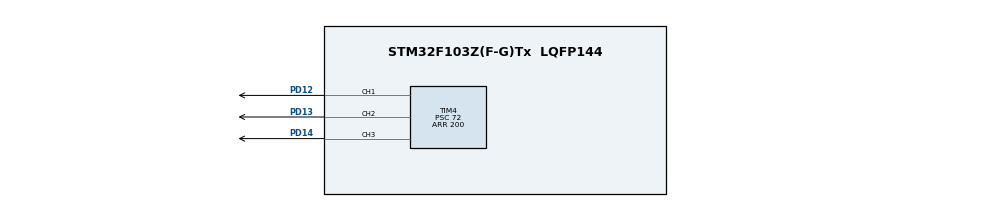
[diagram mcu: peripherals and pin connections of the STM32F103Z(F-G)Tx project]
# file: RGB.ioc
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Mcu.Family=STM32F1
Mcu.Name=STM32F103Z(F-G)Tx
Mcu.Package=LQFP144
NVIC.PriorityGroup=NVIC_PRIORITYGROUP_4
PA13.Mode=Serial_Wire
PA13.Signal=SYS_JTMS-SWDIO
PA14.Mode=Serial_Wire
PA14.Signal=SYS_JTCK-SWCLK
PD12.Signal=S_TIM4_CH1
PD13.Signal=S_TIM4_CH2
PD14.Signal=S_TIM4_CH3
ProjectManager.HeapSize=0x200
ProjectManager.StackSize=0x400
ProjectManager.TargetToolchain=MDK-ARM V5.27
RCC.APB1Freq_Value=8000000
RCC.APB2Freq_Value=8000000
SH.S_TIM4_CH1.0=TIM4_CH1,PWM Generation1 CH1
SH.S_TIM4_CH2.0=TIM4_CH2,PWM Generation2 CH2
SH.S_TIM4_CH3.0=TIM4_CH3,PWM Generation3 CH3
TIM4.Channel-PWM\ Generation1\ CH1=TIM_CHANNEL_1
TIM4.Channel-PWM\ Generation2\ CH2=TIM_CHANNEL_2
TIM4.Channel-PWM\ Generation3\ CH3=TIM_CHANNEL_3
TIM4.Period=200
TIM4.Prescaler=72
board=custom

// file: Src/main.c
/* USER CODE BEGIN Header */
/**
  ******************************************************************************
  * @file           : main.c
  * @brief          : Main program body
  ******************************************************************************
  * @attention
  *
  * <h2><center>&copy; Copyright (c) 2019 STMicroelectronics.
  * All rights reserved.</center></h2>
  *
  * This software component is licensed by ST under BSD 3-Clause license,
  * the "License"; You may not use this file except in compliance with the
  * License. You may obtain a copy of the License at:
  *                        opensource.org/licenses/BSD-3-Clause
  *
  ******************************************************************************
  */
/* USER CODE END Header */

#include "main.h"

/* USER CODE BEGIN PTD */

/*
 * RGB struct
 * https://en.wikipedia.org/wiki/RGB_color_model
 */
struct RGB
{
	unsigned char R;
	unsigned char G;
	unsigned char B;
};

/*
 * HSV struct
 * https://en.wikipedia.org/wiki/HSL_and_HSV
 */
struct HSV
{
	double H;
	double S;
	double V;
};

/* USER CODE END PTD */

TIM_HandleTypeDef htim4;

void SystemClock_Config(void);
static void MX_GPIO_Init(void);
static void MX_TIM4_Init(void);
/* USER CODE BEGIN PFP */

struct RGB HSV2RGB(struct HSV hsv, int scale);

/* USER CODE END PFP */

int main(void)
{

  /* MCU Configuration--------------------------------------------------------*/

  /* Reset of all peripherals, Initializes the Flash interface and the Systick. */
  HAL_Init();

  /* Configure the system clock */
  SystemClock_Config();

  /* Initialize all configured peripherals */
  MX_GPIO_Init();
  MX_TIM4_Init();
  /* USER CODE BEGIN 2 */

  // Init PWM
  HAL_TIM_PWM_Start(&htim4, TIM_CHANNEL_1);
  HAL_TIM_PWM_Start(&htim4, TIM_CHANNEL_2);
  HAL_TIM_PWM_Start(&htim4, TIM_CHANNEL_3);

  // Start PWM
  HAL_TIMEx_PWMN_Start(&htim4, TIM_CHANNEL_1);
  HAL_TIMEx_PWMN_Start(&htim4, TIM_CHANNEL_2);
  HAL_TIMEx_PWMN_Start(&htim4, TIM_CHANNEL_3);

  // Define HSV, RGB
  struct HSV hsv;
  struct RGB rgb;

  /* USER CODE END 2 */

  /* Infinite loop */
  /* USER CODE BEGIN WHILE */
  while (1)
  {
    // Blink rainbow color

  	for (int i = 0; i < 360; i++) {
  		hsv.H = i;
  		hsv.S = 1.0;
  		hsv.V = 1.0;

      // HSV to RGB
  		rgb = HSV2RGB(hsv, 200);

  		// Set PWM duty

  		// Red duty
  		__HAL_TIM_SET_COMPARE(&htim4, TIM_CHANNEL_1, rgb.R);

  		// Green duty
  		__HAL_TIM_SET_COMPARE(&htim4, TIM_CHANNEL_2, rgb.G);

  		// Blue duty
  		__HAL_TIM_SET_COMPARE(&htim4, TIM_CHANNEL_3, rgb.B);

      // Delay 10ms
  		HAL_Delay(10);
  	}
    /* USER CODE END WHILE */

  }
}

void SystemClock_Config(void)
{
  RCC_OscInitTypeDef RCC_OscInitStruct = {0};
  RCC_ClkInitTypeDef RCC_ClkInitStruct = {0};

  /** Initializes the CPU, AHB and APB busses clocks
  */
  RCC_OscInitStruct.OscillatorType = RCC_OSCILLATORTYPE_HSI;
  RCC_OscInitStruct.HSIState = RCC_HSI_ON;
  RCC_OscInitStruct.HSICalibrationValue = RCC_HSICALIBRATION_DEFAULT;
  RCC_OscInitStruct.PLL.PLLState = RCC_PLL_NONE;
  if (HAL_RCC_OscConfig(&RCC_OscInitStruct) != HAL_OK)
  {
    Error_Handler();
  }
  /** Initializes the CPU, AHB and APB busses clocks
  */
  RCC_ClkInitStruct.ClockType = RCC_CLOCKTYPE_HCLK|RCC_CLOCKTYPE_SYSCLK
                              |RCC_CLOCKTYPE_PCLK1|RCC_CLOCKTYPE_PCLK2;
  RCC_ClkInitStruct.SYSCLKSource = RCC_SYSCLKSOURCE_HSI;
  RCC_ClkInitStruct.AHBCLKDivider = RCC_SYSCLK_DIV1;
  RCC_ClkInitStruct.APB1CLKDivider = RCC_HCLK_DIV1;
  RCC_ClkInitStruct.APB2CLKDivider = RCC_HCLK_DIV1;

  if (HAL_RCC_ClockConfig(&RCC_ClkInitStruct, FLASH_LATENCY_0) != HAL_OK)
  {
    Error_Handler();
  }
}

static void MX_TIM4_Init(void)
{

  TIM_MasterConfigTypeDef sMasterConfig = {0};
  TIM_OC_InitTypeDef sConfigOC = {0};

  htim4.Instance = TIM4;
  htim4.Init.Prescaler = 72;
  htim4.Init.CounterMode = TIM_COUNTERMODE_UP;
  htim4.Init.Period = 200;
  htim4.Init.ClockDivision = TIM_CLOCKDIVISION_DIV1;
  htim4.Init.AutoReloadPreload = TIM_AUTORELOAD_PRELOAD_DISABLE;
  if (HAL_TIM_PWM_Init(&htim4) != HAL_OK)
  {
    Error_Handler();
  }
  sMasterConfig.MasterOutputTrigger = TIM_TRGO_RESET;
  sMasterConfig.MasterSlaveMode = TIM_MASTERSLAVEMODE_DISABLE;
  if (HAL_TIMEx_MasterConfigSynchronization(&htim4, &sMasterConfig) != HAL_OK)
  {
    Error_Handler();
  }
  sConfigOC.OCMode = TIM_OCMODE_PWM1;
  sConfigOC.Pulse = 0;
  sConfigOC.OCPolarity = TIM_OCPOLARITY_HIGH;
  sConfigOC.OCFastMode = TIM_OCFAST_DISABLE;
  if (HAL_TIM_PWM_ConfigChannel(&htim4, &sConfigOC, TIM_CHANNEL_1) != HAL_OK)
  {
    Error_Handler();
  }
  if (HAL_TIM_PWM_ConfigChannel(&htim4, &sConfigOC, TIM_CHANNEL_2) != HAL_OK)
  {
    Error_Handler();
  }
  if (HAL_TIM_PWM_ConfigChannel(&htim4, &sConfigOC, TIM_CHANNEL_3) != HAL_OK)
  {
    Error_Handler();
  }
  HAL_TIM_MspPostInit(&htim4);

}

static void MX_GPIO_Init(void)
{

  /* GPIO Ports Clock Enable */
  __HAL_RCC_GPIOD_CLK_ENABLE();
  __HAL_RCC_GPIOA_CLK_ENABLE();

}

/* USER CODE BEGIN 4 */

struct RGB HSV2RGB(struct HSV hsv, int scale) {
	double r = 0, g = 0, b = 0;

	if (hsv.S == 0)
	{
		r = hsv.V;
		g = hsv.V;
		b = hsv.V;
	} else {
		int i;
		double f, p, q, t;

		if (hsv.H == 360)
			hsv.H = 0;
		else
			hsv.H = hsv.H / 60;

		i = (int) hsv.H;
		f = hsv.H - i;

		p = hsv.V * (1.0 - hsv.S);
		q = hsv.V * (1.0 - (hsv.S * f));
		t = hsv.V * (1.0 - (hsv.S * (1.0 - f)));

		switch (i)
		{
		case 0:
			r = hsv.V;
			g = t;
			b = p;
			break;

		case 1:
			r = q;
			g = hsv.V;
			b = p;
			break;

		case 2:
			r = p;
			g = hsv.V;
			b = t;
			break;

		case 3:
			r = p;
			g = q;
			b = hsv.V;
			break;

		case 4:
			r = t;
			g = p;
			b = hsv.V;
			break;

		default:
			r = hsv.V;
			g = p;
			b = q;
			break;
		}
	}

	struct RGB rgb;
	rgb.R = r * scale;
	rgb.G = g * scale;
	rgb.B = b * scale;

	return rgb;
}

/* USER CODE END 4 */

void Error_Handler(void)
{
}

/************************ (C) COPYRIGHT STMicroelectronics *****END OF FILE****/
